# myChip register map
Vendor: ARM Ltd.; Series: ARMCM3; File version: 1.2
CPU: CM3 r2p1, little endian, no MPU, no FPU, 3 interrupt priority bits
Registers are 32-bit, read-write, reset 0x0 unless marked. A register's access mark holds for its fields unless they carry their own. Offsets are from the block's base; [hi:lo] are bit positions; {n}, {i} and the like mark numbered series.

## IWDG
Base 0x4000C000
0x00 KEYR — IWDG Key Register
  [15:0] KEY — IWDG键值（IWDG Key Value）
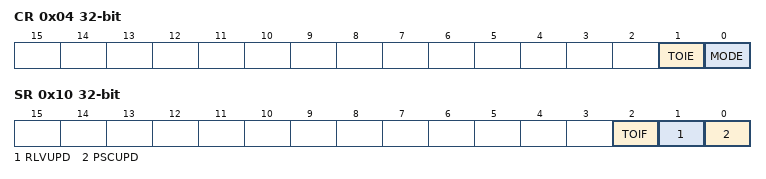
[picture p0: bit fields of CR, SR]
0x04 CR — IWDG Control Register
  [1] TOIE — IWDG超时中断使能位（IWDG Timeout Interrupt Enable）
  [0] MODE — IWDG模式配置位（IWDG Mode Config）
0x08 RLR — IWDG Reload Register
  [15:0] RLV — IWDG重载值（IWDG Reload Value）
0x0C PSCR — IWDG Prescaler Register
  [2:0] PSC — IWDG预分频器（IWDG Prescaler Divider）
0x10 SR — IWDG Status Register
  [2] TOIF — IWDG超时中断标志位（IWDG Timeout Interrupt Flag）
  [1] RLVUPD ro — IWDG计数器重载值更新（IWDG Reload Value Update）
  [0] PSCUPD ro — IWDG预分频器值更新（IWDG Prescaler Update）

## IIR0
Base 0x4003E000
Same registers: IIR1 0x4003E100, IIR2 0x4003E200, IIR3 0x4003E300, IIR4 0x4003E400, IIR5 0x4003E500
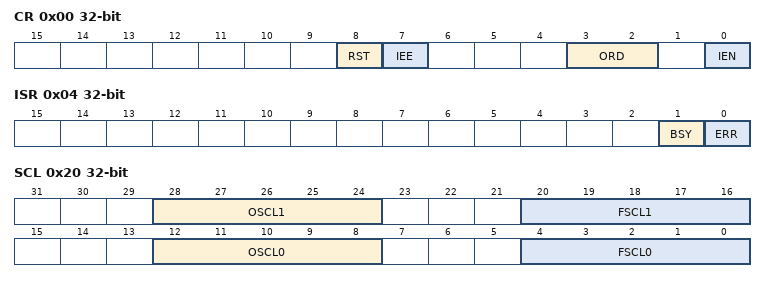
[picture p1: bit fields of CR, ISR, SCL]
0x00 CR — IIR Control Register
  [8] RST — IIR软复位(IIR Soft Reset)
  [7] IEE — IIR错误中断使能位(IIR Error Interrupt Enable)
  [3:2] ORD — IIR阶数选择(IIR Order Selection)
  [0] IEN — IIR使能(IIR Enable)
0x04 ISR — IIR Status Register
  [1] BSY ro — IIR忙标志位(IIR Busy Status)
  [0] ERR — IIR错误中断标志(IIR Error Pending)
0x08 IDR — IIR Data-In Register
  [15:0] ID — IIR数据输入寄存器(IIR Data-In Register)
0x0C ODR — IIR Data-Out Register
  [15:0] OD ro — IIR数据输出寄存器(IIR Data-Out Register)
0x20 SCL — IIR Scale Register
  [28:24] OSCL1 — IIR输出缩放控制位(IIR Output Scale)
  [20:16] FSCL1 — IIR反馈缩放控制位(IIR Feedback Scale)
  [12:8] OSCL0 — IIR输出缩放控制位(IIR Output Scale)
  [4:0] FSCL0 — IIR反馈缩放控制位(IIR Feedback Scale)
{0x30+4i} G0B{i}R (i=0..5) — IIR Group 0 B{i}COEF RegNster
  [26:0] G0B{i}COEF — IIR第0组B{i}系数设置(IIR Group 0 B{i}COEF RegNster)
{0x4C+4i} G0A{i}R (i=1..4) — IIR Group 0 A{i}COEF RegNster
  [26:0] G0A{i}COEF — IIR第0组A{i}系数设置(IIR Group 0 A{i}COEF RegNster)

## HRPWM_MST
Base 0x4003B000
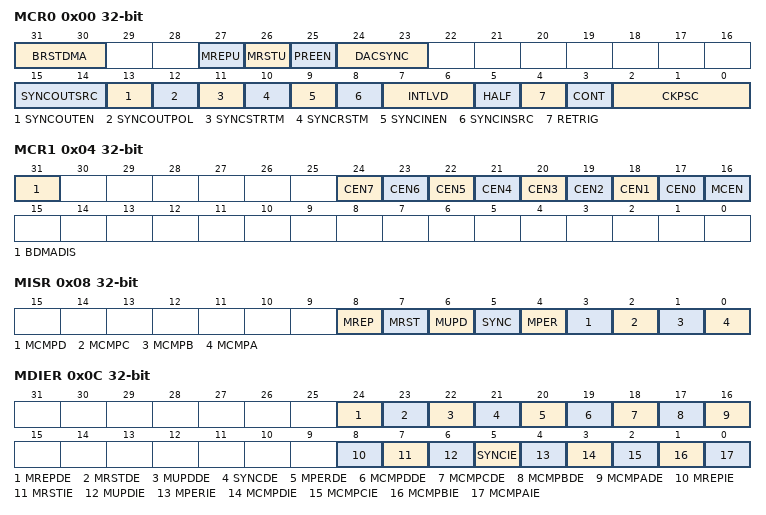
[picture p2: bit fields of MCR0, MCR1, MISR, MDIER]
0x00 MCR0 — HRPWM Master PWM Control Register0
  [31:30] BRSTDMA — Burst DMA 更新
  [27] MREPU — Master PWM Repetition 更新
  [26] MRSTU — Master PWM Reset/RollOver 更新
  [25] PREEN — Master PWM 预加载使能
  [24:23] DACSYNC — DAC Trigger同步
  [15:14] SYNCOUTSRC — 同步事件输出来源
  [13] SYNCOUTEN — 同步事件输出使能
  [12] SYNCOUTPOL — 同步事件输出极性
  [11] SYNCSTRTM — 同步事件启动 Master PWM
  [10] SYNCRSTM — 同步事件复位 Master PWM
  [9] SYNCINEN — 同步事件输入使能
  [8] SYNCINSRC — 同步事件输入来源
  [7:6] INTLVD — Master PWM Interleaved 模式
  [5] HALF — Master PWM Half 模式
  [4] RETRIG — Master PWM 可重触发模式
  [3] CONT — Master PWM 连续模式
  [2:0] CKPSC — Master PWM 时钟预分频比
0x04 MCR1 — HRPWM Master PWM Control Register1
  [31] BDMADIS — Master PWM Burst DMA 禁止
  [n+17] CEN{n} (n=0..7) — PWM{n} 使能
  [16] MCEN — Master PWM 使能
0x08 MISR — HRPWM Master PWM Interrupt Status Register
  [8] MREP — Master Repetition 中断标志
  [7] MRST — Master Reset 中断标志
  [6] MUPD — Master Update 中断标志
  [5] SYNC — Sync Input 中断标志
  [4] MPER — Master Period 中断标志
  [3] MCMPD — Master Compare D 中断标志
  [2] MCMPC — Master Compare C 中断标志
  [1] MCMPB — Master Compare B 中断标志
  [0] MCMPA — Master Compare A 中断标志
0x0C MDIER — HRPWM Master PWM DMA Interrupt Enable Register
  [24] MREPDE — Master Repetition DMA使能
  [23] MRSTDE — Master Reset DMA使能
  [22] MUPDDE — Master Update DMA使能
  [21] SYNCDE — Sync Input DMA使能
  [20] MPERDE — Master Period DMA使能
  [19] MCMPDDE — Master Compare D DMA使能
  [18] MCMPCDE — Master Compare C DMA使能
  [17] MCMPBDE — Master Compare B DMA使能
  [16] MCMPADE — Master Compare A DMA使能
  [8] MREPIE — Master Repetition 中断使能
  [7] MRSTIE — Master Reset 中断使能
  [6] MUPDIE — Master Update 中断使能
  [5] SYNCIE — Sync Input 中断使能
  [4] MPERIE — Master Period 中断使能
  [3] MCMPDIE — Master Compare D 中断使能
  [2] MCMPCIE — Master Compare C 中断使能
  [1] MCMPBIE — Master Compare B 中断使能
  [0] MCMPAIE — Master Compare A 中断使能
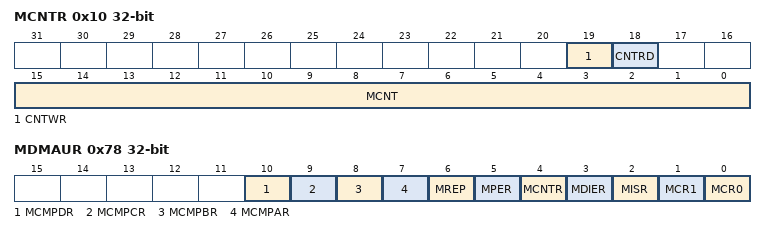
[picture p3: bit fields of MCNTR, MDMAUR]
0x10 MCNTR — HRPWM Master PWM Counter Register
  [19] CNTWR — Master PWM Counter 写入
  [18] CNTRD — Master PWM Counter 读取
  [15:0] MCNT — Master PWM Counter 数值
0x14 MPER — HRPWM Master PWM Period Register
  [15:0] MPER — Master PWM Period 数值
0x18 MREP — HRPWM Master PWM Repetition Register
  [7:0] MREP — Master PWM Repetition Period 数值
0x1C MCMPAR — HRPWM Master PWM Compare A Register
  [15:0] MCMPA — Master PWM Compare A 数值
0x20 MCMPBR — HRPWM Master PWM Compare B Register
  [15:0] MCMPB — Master PWM Compare B 数值
0x24 MCMPCR — HRPWM Master PWM Compare C Register
  [15:0] MCMPC — Master PWM Compare C 数值
0x28 MCMPDR — HRPWM Master PWM Compare D Register
  [15:0] MCMPD — Master PWM Compare D 数值
0x78 MDMAUR — HRPWM Master PWM System DMA Update Register
  [10] MCMPDR — MCMPDR 寄存器支持 System DMA 写入MDMADR并更新
  [9] MCMPCR — MCMPCR 寄存器支持 System DMA 写入MDMADR并更新
  [8] MCMPBR — MCMPBR 寄存器支持 System DMA 写入MDMADR并更新
  [7] MCMPAR — MCMPAR 寄存器支持 System DMA 写入MDMADR并更新
  [6] MREP — MREP 寄存器支持 System DMA 写入MDMADR并更新
  [5] MPER — MPER 寄存器支持 System DMA 写入MDMADR并更新
  [4] MCNTR — MCNTR 寄存器支持 System DMA 写入MDMADR并更新
  [3] MDIER — MDIER 寄存器支持 System DMA 写入MDMADR并更新
  [2] MISR — MISR 寄存器支持 System DMA 写入MDMADR并更新
  [1] MCR1 — MCR1 寄存器支持 System DMA 写入MDMADR并更新
  [0] MCR0 — MCR0 寄存器支持 System DMA 写入MDMADR并更新
0x7C MDMADR — HRPWM Master PWM System DMA Data Register
  [31:0] MDMADR — System DMA 数据地址
